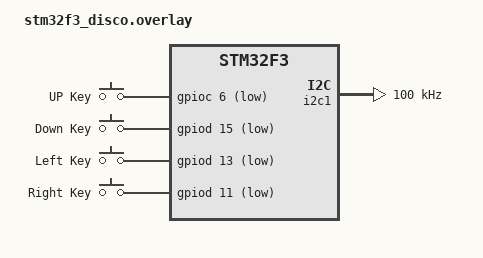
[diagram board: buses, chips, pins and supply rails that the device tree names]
/*
 * Copyright (c) 2025, Muhammad Waleed Badar
 *
 * SPDX-License-Identifier: Apache-2.0
 */

/ {
    hid_dev_0: hid_dev_0 {
		compatible = "zephyr,hid-device";
		protocol-code = "none";
		in-report-size = <64>;
		in-polling-period-us = <1000>;
	};

	gpio_keys {
		compatible = "gpio-keys";
		key_1: button_1 {
			label = "UP Key";
			gpios = <&gpioc 6 (GPIO_ACTIVE_LOW | GPIO_PULL_UP)>;
			zephyr,code = <INPUT_KEY_1>;
		};
		key_2: button_2 {
			label = "Down Key";
			gpios = <&gpiod 15 (GPIO_ACTIVE_LOW | GPIO_PULL_UP)>;
			zephyr,code = <INPUT_KEY_2>;
		};
		key_3: button_3 {
			label = "Left Key";
			gpios = <&gpiod 13 (GPIO_ACTIVE_LOW | GPIO_PULL_UP)>;
			zephyr,code = <INPUT_KEY_3>;
		};
		key_4: button_4 {
			label = "Right Key";
			gpios = <&gpiod 11 (GPIO_ACTIVE_LOW | GPIO_PULL_UP)>;
			zephyr,code = <INPUT_KEY_4>;
		};
	};
};

&i2c1 {
	clock-frequency = <I2C_BITRATE_STANDARD>;
};
